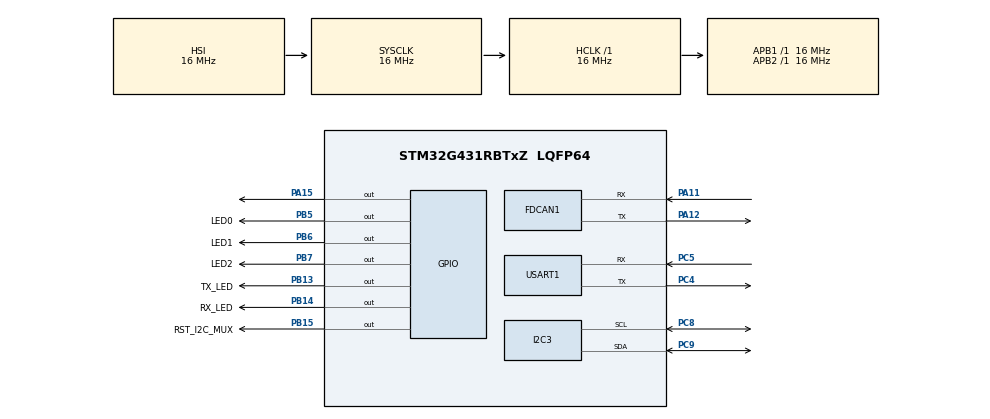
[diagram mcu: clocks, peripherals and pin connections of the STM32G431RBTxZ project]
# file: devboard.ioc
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FDCAN1.CalculateBaudRateNominal=333333
FDCAN1.CalculateTimeBitNominal=3000
FDCAN1.CalculateTimeQuantumNominal=1000.0
I2C3.Timing=0x00503D58
Mcu.Family=STM32G4
Mcu.Name=STM32G431RBTxZ
Mcu.Package=LQFP64
NVIC.PriorityGroup=NVIC_PRIORITYGROUP_4
PA11.Mode=FDCAN_Activate
PA11.Signal=FDCAN1_RX
PA12.Mode=FDCAN_Activate
PA12.Signal=FDCAN1_TX
PA13.Mode=Serial_Wire
PA13.Signal=SYS_JTMS-SWDIO
PA14.Mode=Serial_Wire
PA14.Signal=SYS_JTCK-SWCLK
PA15.Signal=GPIO_Output
PB13.GPIO_Label=TX_LED
PB13.Signal=GPIO_Output
PB14.GPIO_Label=RX_LED
PB14.Signal=GPIO_Output
PB15.GPIO_Label=RST_I2C_MUX
PB15.Signal=GPIO_Output
PB3.Signal=SYS_JTDO-SWO
PB5.GPIO_Label=LED0
PB5.Signal=GPIO_Output
PB6.GPIO_Label=LED1
PB6.Signal=GPIO_Output
PB7.GPIO_Label=LED2
PB7.Signal=GPIO_Output
PC4.Mode=Asynchronous
PC4.Signal=USART1_TX
PC5.Mode=Asynchronous
PC5.Signal=USART1_RX
PC8.Mode=I2C
PC8.Signal=I2C3_SCL
PC9.Mode=I2C
PC9.Signal=I2C3_SDA
ProjectManager.HeapSize=0x200
ProjectManager.StackSize=0x600
ProjectManager.TargetToolchain=CMake
RCC.AHBFreq_Value=16000000
RCC.APB1Freq_Value=16000000
RCC.APB1TimFreq_Value=16000000
RCC.APB2Freq_Value=16000000
RCC.APB2TimFreq_Value=16000000
RCC.CortexFreq_Value=16000000
RCC.EXTERNAL_CLOCK_VALUE=12288000
RCC.HCLKFreq_Value=16000000
RCC.HSE_VALUE=8000000
RCC.HSI48_VALUE=48000000
RCC.HSI_VALUE=16000000
RCC.LSE_VALUE=32768
RCC.SYSCLKFreq_VALUE=16000000
RCC.USBFreq_Value=64000000
RCC.VCOOutputFreq_Value=128000000
USART1.VirtualMode-Asynchronous=VM_ASYNC
USART1.WordLength=WORDLENGTH_9B
VP_PWR_VS_LPOM.Mode=PowerOptimisation
VP_PWR_VS_SECSignals.Mode=Security/Privilege
VP_SYS_VS_DBSignals.Mode=DisableDeadBatterySignals
board=custom

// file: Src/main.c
/* USER CODE BEGIN Header */
/**
  ******************************************************************************
  * @file           : main.c
  * @brief          : Main program body
  ******************************************************************************
  * @attention
  *
  * Copyright (c) 2026 STMicroelectronics.
  * All rights reserved.
  *
  * This software is licensed under terms that can be found in the LICENSE file
  * in the root directory of this software component.
  * If no LICENSE file comes with this software, it is provided AS-IS.
  *
  ******************************************************************************
  */
/* USER CODE END Header */
#include "main.h"

FDCAN_HandleTypeDef hfdcan1;

I2C_HandleTypeDef hi2c3;

UART_HandleTypeDef huart1;

void SystemClock_Config(void);
static void MX_GPIO_Init(void);
static void MX_FDCAN1_Init(void);
static void MX_I2C3_Init(void);
static void MX_USART1_UART_Init(void);

int main(void)
{

  /* MCU Configuration--------------------------------------------------------*/

  /* Reset of all peripherals, Initializes the Flash interface and the Systick. */
  HAL_Init();

  /* Configure the system clock */
  SystemClock_Config();

  /* Initialize all configured peripherals */
  MX_GPIO_Init();
  MX_FDCAN1_Init();
  MX_I2C3_Init();
  MX_USART1_UART_Init();

  /* Infinite loop */
  /* USER CODE BEGIN WHILE */
  while (1)
  {
    LED_TEST();
    /* USER CODE END WHILE */

  }
}

void SystemClock_Config(void)
{
  RCC_OscInitTypeDef RCC_OscInitStruct = {0};
  RCC_ClkInitTypeDef RCC_ClkInitStruct = {0};

  /** Configure the main internal regulator output voltage
  */
  HAL_PWREx_ControlVoltageScaling(PWR_REGULATOR_VOLTAGE_SCALE1);

  /** Initializes the RCC Oscillators according to the specified parameters
  * in the RCC_OscInitTypeDef structure.
  */
  RCC_OscInitStruct.OscillatorType = RCC_OSCILLATORTYPE_HSI;
  RCC_OscInitStruct.HSIState = RCC_HSI_ON;
  RCC_OscInitStruct.HSICalibrationValue = RCC_HSICALIBRATION_DEFAULT;
  RCC_OscInitStruct.PLL.PLLState = RCC_PLL_NONE;
  if (HAL_RCC_OscConfig(&RCC_OscInitStruct) != HAL_OK)
  {
    Error_Handler();
  }

  /** Initializes the CPU, AHB and APB buses clocks
  */
  RCC_ClkInitStruct.ClockType = RCC_CLOCKTYPE_HCLK|RCC_CLOCKTYPE_SYSCLK
                              |RCC_CLOCKTYPE_PCLK1|RCC_CLOCKTYPE_PCLK2;
  RCC_ClkInitStruct.SYSCLKSource = RCC_SYSCLKSOURCE_HSI;
  RCC_ClkInitStruct.AHBCLKDivider = RCC_SYSCLK_DIV1;
  RCC_ClkInitStruct.APB1CLKDivider = RCC_HCLK_DIV1;
  RCC_ClkInitStruct.APB2CLKDivider = RCC_HCLK_DIV1;

  if (HAL_RCC_ClockConfig(&RCC_ClkInitStruct, FLASH_LATENCY_0) != HAL_OK)
  {
    Error_Handler();
  }
}

static void MX_FDCAN1_Init(void)
{

  hfdcan1.Instance = FDCAN1;
  hfdcan1.Init.ClockDivider = FDCAN_CLOCK_DIV1;
  hfdcan1.Init.FrameFormat = FDCAN_FRAME_CLASSIC;
  hfdcan1.Init.Mode = FDCAN_MODE_NORMAL;
  hfdcan1.Init.AutoRetransmission = DISABLE;
  hfdcan1.Init.TransmitPause = DISABLE;
  hfdcan1.Init.ProtocolException = DISABLE;
  hfdcan1.Init.NominalPrescaler = 16;
  hfdcan1.Init.NominalSyncJumpWidth = 1;
  hfdcan1.Init.NominalTimeSeg1 = 1;
  hfdcan1.Init.NominalTimeSeg2 = 1;
  hfdcan1.Init.DataPrescaler = 1;
  hfdcan1.Init.DataSyncJumpWidth = 1;
  hfdcan1.Init.DataTimeSeg1 = 1;
  hfdcan1.Init.DataTimeSeg2 = 1;
  hfdcan1.Init.StdFiltersNbr = 0;
  hfdcan1.Init.ExtFiltersNbr = 0;
  hfdcan1.Init.TxFifoQueueMode = FDCAN_TX_FIFO_OPERATION;
  if (HAL_FDCAN_Init(&hfdcan1) != HAL_OK)
  {
    Error_Handler();
  }

}

static void MX_I2C3_Init(void)
{

  hi2c3.Instance = I2C3;
  hi2c3.Init.Timing = 0x00503D58;
  hi2c3.Init.OwnAddress1 = 0;
  hi2c3.Init.AddressingMode = I2C_ADDRESSINGMODE_7BIT;
  hi2c3.Init.DualAddressMode = I2C_DUALADDRESS_DISABLE;
  hi2c3.Init.OwnAddress2 = 0;
  hi2c3.Init.OwnAddress2Masks = I2C_OA2_NOMASK;
  hi2c3.Init.GeneralCallMode = I2C_GENERALCALL_DISABLE;
  hi2c3.Init.NoStretchMode = I2C_NOSTRETCH_DISABLE;
  if (HAL_I2C_Init(&hi2c3) != HAL_OK)
  {
    Error_Handler();
  }

  /** Configure Analogue filter
  */
  if (HAL_I2CEx_ConfigAnalogFilter(&hi2c3, I2C_ANALOGFILTER_ENABLE) != HAL_OK)
  {
    Error_Handler();
  }

  /** Configure Digital filter
  */
  if (HAL_I2CEx_ConfigDigitalFilter(&hi2c3, 0) != HAL_OK)
  {
    Error_Handler();
  }

}

static void MX_USART1_UART_Init(void)
{

  huart1.Instance = USART1;
  huart1.Init.BaudRate = 115200;
  huart1.Init.WordLength = UART_WORDLENGTH_9B;
  huart1.Init.StopBits = UART_STOPBITS_1;
  huart1.Init.Parity = UART_PARITY_NONE;
  huart1.Init.Mode = UART_MODE_TX_RX;
  huart1.Init.HwFlowCtl = UART_HWCONTROL_NONE;
  huart1.Init.OverSampling = UART_OVERSAMPLING_16;
  huart1.Init.OneBitSampling = UART_ONE_BIT_SAMPLE_DISABLE;
  huart1.Init.ClockPrescaler = UART_PRESCALER_DIV1;
  huart1.AdvancedInit.AdvFeatureInit = UART_ADVFEATURE_NO_INIT;
  if (HAL_UART_Init(&huart1) != HAL_OK)
  {
    Error_Handler();
  }
  if (HAL_UARTEx_SetTxFifoThreshold(&huart1, UART_TXFIFO_THRESHOLD_1_8) != HAL_OK)
  {
    Error_Handler();
  }
  if (HAL_UARTEx_SetRxFifoThreshold(&huart1, UART_RXFIFO_THRESHOLD_1_8) != HAL_OK)
  {
    Error_Handler();
  }
  if (HAL_UARTEx_DisableFifoMode(&huart1) != HAL_OK)
  {
    Error_Handler();
  }

}

static void MX_GPIO_Init(void)
{
  GPIO_InitTypeDef GPIO_InitStruct = {0};

  /* GPIO Ports Clock Enable */
  __HAL_RCC_GPIOC_CLK_ENABLE();
  __HAL_RCC_GPIOB_CLK_ENABLE();
  __HAL_RCC_GPIOA_CLK_ENABLE();

  /*Configure GPIO pin Output Level */
  HAL_GPIO_WritePin(GPIOB, TX_LED_Pin|RX_LED_Pin|RST_I2C_MUX_Pin|LED0_Pin
                          |LED1_Pin|LED2_Pin, GPIO_PIN_RESET);

  /*Configure GPIO pin Output Level */
  HAL_GPIO_WritePin(GPIOA, GPIO_PIN_15, GPIO_PIN_RESET);

  /*Configure GPIO pins : TX_LED_Pin RX_LED_Pin RST_I2C_MUX_Pin LED0_Pin
                           LED1_Pin LED2_Pin */
  GPIO_InitStruct.Pin = TX_LED_Pin|RX_LED_Pin|RST_I2C_MUX_Pin|LED0_Pin
                          |LED1_Pin|LED2_Pin;
  GPIO_InitStruct.Mode = GPIO_MODE_OUTPUT_PP;
  GPIO_InitStruct.Pull = GPIO_NOPULL;
  GPIO_InitStruct.Speed = GPIO_SPEED_FREQ_LOW;
  HAL_GPIO_Init(GPIOB, &GPIO_InitStruct);

  /*Configure GPIO pin : PA15 */
  GPIO_InitStruct.Pin = GPIO_PIN_15;
  GPIO_InitStruct.Mode = GPIO_MODE_OUTPUT_PP;
  GPIO_InitStruct.Pull = GPIO_NOPULL;
  GPIO_InitStruct.Speed = GPIO_SPEED_FREQ_LOW;
  HAL_GPIO_Init(GPIOA, &GPIO_InitStruct);

}

void Error_Handler(void)
{
  __disable_irq();
  while (1)
  {
  }
}
